# PY32F002Axx register map
Vendor: Puya; Series: PY32F0; File version: 1.0.0
CPU: CM0+ r0p1, little endian, no MPU, no FPU, 4 interrupt priority bits
Registers are 32-bit, read-write, reset 0x0 unless marked. A register's access mark holds for its fields unless they carry their own. Offsets are from the block's base; [hi:lo] are bit positions; {n}, {i} and the like mark numbered series; 'fields as' and 'values as' point back to an identical list.

## LPTIM — Low power timer
Base 0x40007C00
0x00 ISR ro — Interrupt and Status Register
  [1] ARRM — Autoreload match
    1=Set (Autoreload match)
0x04 ICR wo — Interrupt Clear Register
  [1] ARRMCF — Autoreload match Clear Flag
    1=Clear (Autoreload match Clear Flag)
0x08 IER — Interrupt Enable Register
  [1] ARRMIE — Autoreload match Interrupt Enable
    0=Disabled (ARRM interrupt disabled); 1=Enabled (ARRM interrupt enabled)
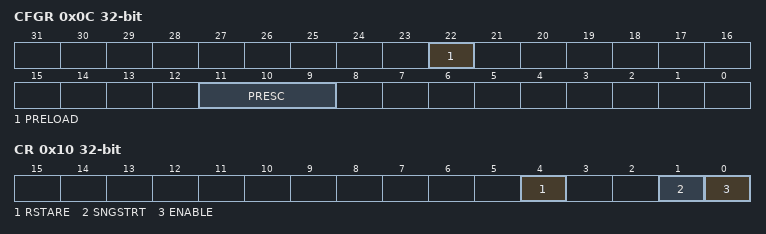
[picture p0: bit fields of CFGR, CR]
0x0C CFGR — Configuration Register
  [22] PRELOAD — Registers update mode
    0=Immediate (Registers are updated after each APB bus write access); 1=EndOfPeriod (Registers are updated at the end of the current LPTIM period)
  [11:9] PRESC — Clock prescaler
    0=Div1 (/1); 1=Div2 (/2); 2=Div4 (/4); 3=Div8 (/8); 4=Div16 (/16); 5=Div32 (/32); 6=Div64 (/64); 7=Div128 (/128)
0x10 CR — Control Register
  [4] RSTARE — Reset after read enable
    0=Disabled (CNT Register reads do not trigger reset); 1=Enabled (CNT Register reads trigger reset of LPTIM)
  [1] SNGSTRT — LPTIM start in single mode
    on write: 1=Start (LPTIM start in Single mode)
  [0] ENABLE — LPTIM Enable
    0=Disabled (LPTIM is disabled); 1=Enabled (LPTIM is enabled)
0x18 ARR reset 0x1 — Autoreload Register
  [15:0] ARR — Auto reload value
0x1C CNT ro — Counter Register
  [15:0] CNT — Counter value

## IWDG — Independent watchdog
Base 0x40003000
0x00 KR wo — Key register (IWDG_KR)
  [15:0] KEY — Key value
    0x5555=Enable access to PR, RLR and WINR registers (0x5555); 0xAAAA=Reset the watchdog value (0xAAAA); 0xCCCC=Start the watchdog (0xCCCC)
0x04 PR — Prescaler register (IWDG_PR)
  [2:0] PR — Prescaler divider
    0=DivideBy4 (Divider /4); 1=DivideBy8 (Divider /8); 2=DivideBy16 (Divider /16); 3=DivideBy32 (Divider /32); 4=DivideBy64 (Divider /64); 5=DivideBy128 (Divider /128); 6=DivideBy256 (Divider /256); 7=DivideBy256bis (Divider /256)
0x08 RLR reset 0xFFF — Reload register (IWDG_RLR)
  [11:0] RL — Watchdog counter reload value
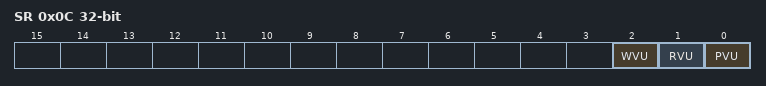
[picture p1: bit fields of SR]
0x0C SR ro — Status register (IWDG_SR)
  [all] fields
    0=Idle (No update on-going); 1=Busy (Update on-going)
  [2] WVU — Watchdog counter window value update
  [1] RVU — Watchdog counter reload value update
  [0] PVU — Watchdog prescaler value update
0x10 WINR ro — Window register (IWDG_SR)
  [11:0] WIN — window counter

## TIM16 — General purpose timer
Base 0x40014400
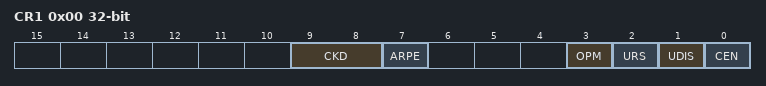
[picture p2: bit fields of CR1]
0x00 CR1 — TIM16 control register1
  [9:8] CKD — Prescaler factor
  [7] ARPE — Auto-reload preload enable
    0=Disabled (TIMx_APRR register is not buffered); 1=Enabled (TIMx_APRR register is buffered)
  [3] OPM — One pulse mode
  [2] URS — Update request source
    0=AnyEvent (Any of counter overflow/underflow, setting UG, or update through slave mode, generates an update interrupt or DMA request); 1=CounterOnly (Only counter overflow/underflow generates an update interrupt or DMA request)
  [1] UDIS — Update disable
    0=Enabled (Update event enabled); 1=Disabled (Update event disabled)
  [0] CEN — Counter enable
    0=Disabled (Counter disabled); 1=Enabled (Counter enabled)
0x0C DIER — DMA/Interrupt enable register
  [0] UIE — Update interrupt enable
0x10 SR — status register
  [0] UIF — Update interrupt flag
0x14 EGR wo — event generation register
  [0] UG — Update generation
    1=Trigger (Re-initializes the timer counter and generates an update of the registers.)
0x24 CNT — counter
  [15:0] CNT — counter value
0x28 PSC — prescaler
  [15:0] PSC — Prescaler value
0x2C ARR — auto-reload register
  [15:0] ARR — Auto-reload value
0x30 RCR — repetition counter register
  [7:0] REP — Repetition counter value

## SYSCFG — System configuration controller
Base 0x40010000
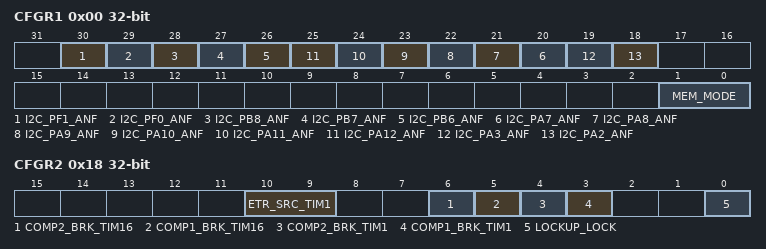
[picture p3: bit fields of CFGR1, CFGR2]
0x00 CFGR1 — SYSCFG configuration register 1
  [30] I2C_PF1_ANF — Analog filter enable control driving capability activation bits PF1
    0=Standard (Pin operate in standard mode); 1=AnalogFilter (I2C Analog filter enabled on pin)
  [29] I2C_PF0_ANF — Analog filter enable control driving capability activation bits PF0
    values as I2C_PF1_ANF
  [28] I2C_PB8_ANF — Analog filter enable control driving capability activation bits PB8
    values as I2C_PF1_ANF
  [27] I2C_PB7_ANF — Analog filter enable control driving capability activation bits PB7
    values as I2C_PF1_ANF
  [26] I2C_PB6_ANF — Analog filter enable control driving capability activation bits PB6
    values as I2C_PF1_ANF
  [n+13] I2C_PA{n}_ANF (n=7..12) — Analog filter enable control driving capability activation bits PA{n}
    values as I2C_PF1_ANF
  [19] I2C_PA3_ANF — Analog filter enable control driving capability activation bits PA3
    values as I2C_PF1_ANF
  [18] I2C_PA2_ANF — Analog filter enable control driving capability activation bits PA2
    values as I2C_PF1_ANF
  [1:0] MEM_MODE — Memory mapping selection bits
    0=Main Flash memory mapped at 0x0000_0000; 1=System Flash memory mapped at 0x0000_0000; 2=MainFlash2 (Main Flash memory mapped at 0x0000_0000); 3=SRAM (Embedded SRAM mapped at 0x0000_0000)
0x18 CFGR2 — SYSCFG configuration register 2
  [10:9] ETR_SRC_TIM1 — TIM1 ETR source selection
    0=GPIO (TIM1_ETR is connected to GPIO); 1=COMP1 (TIM1_ETR is connected to COMP1); 2=COMP2 (TIM1_ETR is connected to COMP2); 3=ADC (TIM1_ETR is connected to ADC)
  [6] COMP2_BRK_TIM16 — COMP2 output connect to TIM16 Break input
    0=Disconnected (COMP? output not connect to TIM? Break input); 1=Connected (COMP? output connected to TIM? Break input)
  [5] COMP1_BRK_TIM16 — COMP1 output connect to TIM16 Break input
    values as COMP2_BRK_TIM16
  [4] COMP2_BRK_TIM1 — COMP2 output connect to TIM1 Break input
    values as COMP2_BRK_TIM16
  [3] COMP1_BRK_TIM1 — COMP1 output connect to TIM1 Break input
    values as COMP2_BRK_TIM16
  [0] LOCKUP_LOCK — Cortex-M0+ LOCKUP bit enable bit
    0=Disconnected (Cortex-M0+ LOCKUP output disconnected from TIM1/16/17 Break input); 1=Connected (Cortex-M0+ LOCKUP output connected to TIM1/16/17 Break input)
